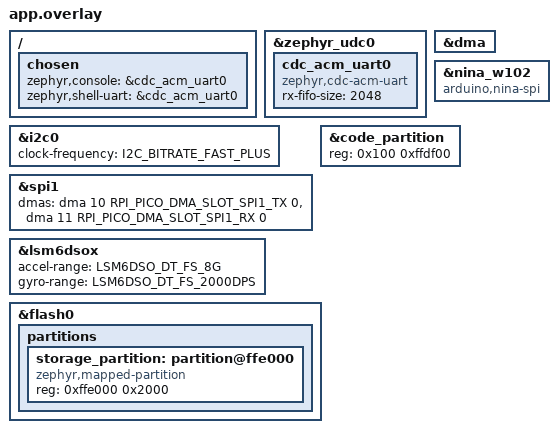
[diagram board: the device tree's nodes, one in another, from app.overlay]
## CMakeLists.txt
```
cmake_minimum_required(VERSION 3.28.0)
# The NINA-W102's devicetree binding (arduino,nina-spi) is its Zephyr binding's.
list(APPEND DTS_ROOT ${CMAKE_CURRENT_SOURCE_DIR}/../../../common/drivers/nina/port/zephyr)
# The LSM6DSO driver's Zephyr binding is a Zephyr module of its own (zephyr/module.yml there).
list(APPEND ZEPHYR_EXTRA_MODULES ${CMAKE_CURRENT_SOURCE_DIR}/../../../common/drivers/lsm6dso/port/zephyr)
find_package(Zephyr REQUIRED HINTS $ENV{ZEPHYR_BASE})
project(usb_console)

# Sources shared with the NuttX build.
set(COMMON_DIR ${CMAKE_CURRENT_SOURCE_DIR}/../../../common)
cmake_path(NORMAL_PATH COMMON_DIR)

target_sources(app PRIVATE src/main.c ${COMMON_DIR}/imu/app_main.c src/log_ram.c ${COMMON_DIR}/imu/kv_store.c ${COMMON_DIR}/imu/imu_cal.c
  ${COMMON_DIR}/imu/imu_cal_codec.c ${COMMON_DIR}/imu/wifi_profile.c
  ${COMMON_DIR}/imu/time_sync.c ${COMMON_DIR}/imu/time_offset.c
  ${COMMON_DIR}/imu/imu_stream.c ${COMMON_DIR}/imu/imu_raw_batch.c ${COMMON_DIR}/imu/imu_raw_packet.c
  ${COMMON_DIR}/imu/imu_raw_time.c ${COMMON_DIR}/imu/imu_tick_clock.c ${COMMON_DIR}/imu/imu_raw_queue.c
  ${COMMON_DIR}/imu/imu_raw_mqtt.c ${COMMON_DIR}/imu/imu_raw_status.c)
# Last below, common/chip/rp2040/include: the RP2040's code that no OS owns (the TIMER's read,
# the watchdog's restart), shared with the NuttX and FreeRTOS builds.
target_include_directories(app PRIVATE src ${COMMON_DIR}/imu
  ${COMMON_DIR}/drivers/nina/include ${COMMON_DIR}/drivers/nina/internal ${COMMON_DIR}/drivers/nina/port
  ${COMMON_DIR}/chip/rp2040/include)
# The LSM6DSO driver is the shared one of common/drivers/lsm6dso: its core and its Zephyr
# binding, a Zephyr module (port/zephyr, ZEPHYR_EXTRA_MODULES above) whose option
# CONFIG_LSM6DSO_LOCAL replaces Zephyr's CONFIG_LSM6DSO and whose build rules make a library of
# its own and export the driver's extended API <zephyr/drivers/sensor/lsm6dso.h>.  The sensor
# shell is Zephyr's with the local patch 0006 (manifest/zephyr/patches/zephyr).
# "kernel ps" (main.c): the interval arithmetic shared with the FreeRTOS build's "ps"
# (common/shell/include/ps_interval.h), and the kernel's internal headers for the interrupt stack
# (z_stack_space_get(), as Thread Analyzer).
set_property(SOURCE src/main.c APPEND PROPERTY INCLUDE_DIRECTORIES ${COMMON_DIR}/shell/include
  ${ZEPHYR_BASE}/kernel/include ${ZEPHYR_BASE}/arch/${ARCH}/include)

# NINA-W102: the shared core of common/drivers/nina (the Wi-Fi operations nina_wifi.c, the
# socket table and commands nina_sock.c, the resolver nina_dns.c; in internal/ the SPI link
# nina_proto.c and the socket loops' waits nina_wait.c), its Zephyr binding in
# common/drivers/nina/port/zephyr (the Wi-Fi management and network interface nina_net.c, the
# kernel services of port/nina_os.h nina_os.c: locks, requests, sleeps, clock, the READY and IRQ
# interrupts, the socket offload nina_socket.c, and spi1 and the module's lines from the
# devicetree nina_bus.c) and the "nina" command common/shell/nina_shell.c.  The core's POSIX
# socket names come from common/drivers/nina/port/zephyr/posix, on the include path of the
# socket sources only.  The binding's devicetree binding and options are its own
# (port/zephyr/dts/bindings, port/zephyr/Kconfig: DTS_ROOT above, the app's Kconfig).
set(nina_dir ${COMMON_DIR}/drivers/nina)
set(nina_internal_dir ${nina_dir}/internal)
set(nina_zephyr_dir ${nina_dir}/port/zephyr)
target_sources(app PRIVATE ${nina_internal_dir}/nina_proto.c ${nina_zephyr_dir}/nina_bus.c
  ${nina_zephyr_dir}/nina_os.c ${nina_dir}/nina_wifi.c ${nina_zephyr_dir}/nina_net.c ${nina_dir}/nina_sock.c
  ${nina_zephyr_dir}/nina_socket.c ${nina_dir}/nina_dns.c ${COMMON_DIR}/shell/nina_shell.c
  ${nina_internal_dir}/nina_wait.c)
# The NINA passthrough mode for esptool: the driver's core common/drivers/nina/nina_passthrough.c,
# its host's side on Zephyr's USB device stack (the binding's nina_passthrough_os.c) and its
# module's side on the Pico SDK's registers of hal_rpi_pico (the binding's
# nina_passthrough_bus_rp2040.c).  main() runs it on request, and "nina passthrough" is an entry
# of nina_shell.c's set.  While the mode is active nina_passthrough_active() keeps nina_bus.c
# from the module's lines.
if(CONFIG_NINA_PASSTHROUGH)
  target_sources(app PRIVATE ${nina_dir}/nina_passthrough.c ${nina_zephyr_dir}/nina_passthrough_os.c
    ${nina_zephyr_dir}/nina_passthrough_bus_rp2040.c)
endif()
set(nina_socket_sources ${nina_dir}/nina_sock.c ${nina_zephyr_dir}/nina_socket.c
  ${nina_dir}/nina_dns.c)
set_property(SOURCE ${nina_socket_sources} ${nina_zephyr_dir}/nina_net.c APPEND PROPERTY
  INCLUDE_DIRECTORIES ${nina_zephyr_dir}/posix)
# The resolver registered as the offload's, its results on nina_socket.c's heap (nina_os.h).
set_property(SOURCE ${nina_socket_sources} APPEND PROPERTY COMPILE_DEFINITIONS NINA_OS_DNS_OFFLOAD)
# Integer division through the SIO divider: the Pico SDK's pico_divider (hal_rpi_pico), as the
# SDK's pico_divider_hardware links it.  libgcc defines the plain names, so the references are
# wrapped to the SDK's __wrap___aeabi_idiv, ...  The routines save the divider when they
# interrupt a division (PICO_DIVIDER_DISABLE_INTERRUPTS=0); the thread switches save it
# (CONFIG_ARM_RP2040_DIVIDER_SAVE, manifest/zephyr/patches).  Division by zero still calls
# libgcc's __aeabi_idiv0 and __aeabi_ldiv0, which return; the 64-bit results are libgcc's, but a
# 32-bit quotient is then saturated (libgcc: 0) and the remainder 0 (libgcc: the dividend).
if(CONFIG_RP2040_PICO_DIVIDER)
  if(NOT CONFIG_ARM_RP2040_DIVIDER_SAVE)
    message(FATAL_ERROR "CONFIG_RP2040_PICO_DIVIDER needs CONFIG_ARM_RP2040_DIVIDER_SAVE: "
      "apply the local patches (source script/setup.sh)")
  endif()
  set(pico_src_dir ${ZEPHYR_HAL_RPI_PICO_MODULE_DIR}/src)
  set(divider_asm ${pico_src_dir}/rp2_common/pico_divider/divider_hardware.S)
  target_sources(app PRIVATE ${divider_asm})
  set_source_files_properties(${divider_asm} PROPERTIES
    COMPILE_DEFINITIONS PICO_DIVIDER_DISABLE_INTERRUPTS=0
    INCLUDE_DIRECTORIES "${pico_src_dir}/rp2_common/hardware_divider/include;${pico_src_dir}/rp2040/pico_platform/include")
  foreach(sym __aeabi_idiv __aeabi_idivmod __aeabi_uidiv __aeabi_uidivmod __aeabi_ldivmod
          __aeabi_uldivmod)
    zephyr_ld_options(-Wl,--wrap=${sym})
  endforeach()
endif()

# The DesignWare I2C driver is Zephyr's with a local patch (manifest/zephyr/patches/zephyr/
# 0003-i2c-dw-rp2040-fifo-and-dma.patch: the RP2040's FIFO depth and CONFIG_I2C_DW_RP2040_DMA,
# whole in Zephyr's tree). The "i2c_dma" command is the shared one
# (common/shell/i2c_dma_shell.c, on the functions of
# <zephyr/drivers/i2c/i2c_dw_rp2040_dma.h> that the patched driver defines).
if(CONFIG_I2C_DW_RP2040_DMA AND CONFIG_SHELL)
  target_sources(app PRIVATE ${COMMON_DIR}/shell/i2c_dma_shell.c)
endif()

# The code of the sensor's and the send's paths runs from RAM: the list and the check after the
# link are in ram_code.cmake.
include(ram_code.cmake)
```

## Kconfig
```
mainmenu "USB console"
source "Kconfig.zephyr"

config RP2040_PICO_DIVIDER
	bool "Integer division through the RP2040 hardware divider"
	default y
	depends on SOC_RP2040 && !SMP
	select ARM_RP2040_DIVIDER_SAVE
	help
	  Wrap __aeabi_idiv(), __aeabi_idivmod(), __aeabi_uidiv(),
	  __aeabi_uidivmod(), __aeabi_ldivmod() and __aeabi_uldivmod() (the
	  linker's --wrap) to the Pico SDK's pico_divider routines
	  (divider_hardware.S of hal_rpi_pico), which use the SIO divider.
	  Without it they are libgcc's shift-and-subtract loops. The routines
	  save the divider around their use when they interrupt another
	  division; the thread switches save and restore it
	  (ARM_RP2040_DIVIDER_SAVE, a local patch of Zephyr applied by
	  script/setup.sh).

rsource "../../../common/drivers/nina/port/zephyr/Kconfig"

config NINA_PASSTHROUGH
	bool "NINA passthrough mode for esptool"
	default y
	depends on WIFI_NINA_LOCAL && SOC_RP2040 && SHELL
	depends on USBD_CDC_ACM_CLASS && CDC_ACM_SERIAL_INITIALIZE_AT_BOOT && UART_LINE_CTRL
	help
	  The "nina passthrough confirm" command: a restart into a mode that
	  relays the USB CDC ACM port to the NINA-W102's UART (UART1 on
	  GPIO8 and GPIO9, the pins of the NINA's SPI link), with DTR and RTS
	  on the module's GPIO0 and RESETN, so that esptool on the PC reads
	  and writes the module's flash (common/drivers/nina/nina_passthrough.c).
	  Closing the port at 300 bps or the RESET button ends it.

config NINA_NTP_SERVER
	string "NTP server hostname or IPv4 address"
	default ""
	depends on WIFI_NINA_LOCAL
	help
	  Empty uses the default gateway, normally the PC that provides the
	  Wi-Fi network and runs an NTP server for the board.

config NINA_NTP_PORT
	int "NTP server UDP port"
	default 123
	range 1 65535
	depends on WIFI_NINA_LOCAL

config NINA_NTP_INTERVAL_MS
	int "Interval between NTP queries in milliseconds"
	default 2000
	range 250 3600000
	depends on WIFI_NINA_LOCAL
	help
	  Queries go to a server on the local network. Do not point short
	  intervals at public servers.

# The application's modules (common/imu), which this build always has.
# The NuttX build has the same symbols as options; the application's start
# (common/imu/app_main.c, common/imu/app_main.h) starts only the modules
# whose symbol is set.

config KV_STORE
	def_bool y
	help
	  The key-value store (common/imu/kv_store.c).

config APP_IMU
	def_bool y
	help
	  The IMU acquisition service with its calibration and the time
	  synchronization (common/imu/imu_stream.c, imu_cal.c, time_sync.c).

config WIFI_PROFILE
	def_bool y
	depends on WIFI_CREDENTIALS
	help
	  The Wi-Fi profile and its automatic connection
	  (common/imu/wifi_profile.c).
```

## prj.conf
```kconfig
CONFIG_SERIAL=y
CONFIG_CONSOLE=y
CONFIG_UART_CONSOLE=y
CONFIG_UART_LINE_CTRL=y
CONFIG_SHELL=y
CONFIG_SHELL_HISTORY=y
CONFIG_SHELL_BACKEND_SERIAL_RX_RING_BUFFER_SIZE=2048
CONFIG_SHELL_CMD_BUFF_SIZE=512
CONFIG_SHELL_STACK_SIZE=3072
CONFIG_MAIN_STACK_SIZE=2048
CONFIG_GPIO=y
CONFIG_GPIO_SHELL=y
CONFIG_I2C=y
CONFIG_SPI=y
CONFIG_I2C_SHELL=y
CONFIG_I2C_SHELL_BUFFER_SIZE=64
CONFIG_SENSOR=y
CONFIG_SENSOR_SHELL=y
CONFIG_SENSOR_SHELL_STREAM=y
CONFIG_SENSOR_SHELL_THREAD_STACK_SIZE=3072
CONFIG_STACK_SENTINEL=y
CONFIG_POLL=y
# The LSM6DSOX: the shared driver of common/drivers/lsm6dso (its Kconfig, sourced by the app's),
# not Zephyr's driver of the same devices.
CONFIG_LSM6DSO=n
CONFIG_LSM6DSO_LOCAL=y
CONFIG_REBOOT=y
# Reboot after a fatal error instead of halting; the report stays in the RAM log.
CONFIG_RESET_ON_FATAL_ERROR=y
# memcpy() and memset() through the bootrom's routines instead of picolibc's byte loops (a local
# patch of Zephyr, manifest/zephyr/patches, applied by script/setup.sh).
CONFIG_RP2040_ROM_MEM_OPS=y
# The code of the sensor's and the send's paths runs from RAM (ram_code.cmake).
CONFIG_CODE_DATA_RELOCATION=y
CONFIG_THREAD_ANALYZER=y
CONFIG_THREAD_ANALYZER_USE_PRINTK=y
CONFIG_LOG=y
CONFIG_LOG_OUTPUT=y
CONFIG_LOG_TIMESTAMP_64BIT=y
CONFIG_LOG_CMDS=y
CONFIG_LOG_RUNTIME_FILTERING=y
CONFIG_SHELL_LOG_BACKEND=n
CONFIG_LOG_BACKEND_UART=n

CONFIG_USB_DEVICE_STACK_NEXT=y
CONFIG_USBD_CDC_ACM_LOG_LEVEL_OFF=y
# Run the CDC ACM class (the USB shell's transmit completions) on its own work
# queue instead of the system work queue. There, zperf's idle_work_handler()
# waits for srv_lock, which "zperf tcp download stop" holds while it prints to
# the USB shell; the shell then waits for the work queue and both stop.
CONFIG_USBD_CDC_ACM_WORKQUEUE=y
CONFIG_CDC_ACM_SERIAL_INITIALIZE_AT_BOOT=y
CONFIG_CDC_ACM_SERIAL_PID=0x0004
CONFIG_CDC_ACM_SERIAL_PRODUCT_STRING="Zephyr USB Console"

# Measure active time from CPU idle windows, including interrupts.
CONFIG_CPU_LOAD=y
CONFIG_CPU_LOAD_BACKEND_IDLE_HOOK=y

# Use DMA for eligible I2C0 reads.
CONFIG_DMA=y
CONFIG_I2C_DW_RP2040_DMA=y

# The NINA's SPI1 through the DMA from 64 bytes (the channels in app.overlay);
# shorter transfers stay polled (patch 0007).
CONFIG_SPI_PL022_DMA=y
CONFIG_SPI_PL022_DMA_MIN_LEN=64

# NINA Wi-Fi management and socket offload.
CONFIG_NETWORKING=y
CONFIG_WIFI=y
CONFIG_WIFI_CREDENTIALS=y
CONFIG_WIFI_CREDENTIALS_BACKEND_SETTINGS=y
CONFIG_WIFI_NINA_LOCAL=y
CONFIG_NET_IPV4=y
CONFIG_NET_TCP=y
CONFIG_SHELL_BACKEND_TELNET=y
CONFIG_ZVFS_POLL_MAX=16
CONFIG_NET_ZPERF=y
CONFIG_NET_ZPERF_IPERF3=y
CONFIG_NET_ZPERF_SERVER=y
CONFIG_NET_L2_WIFI_SHELL=y
CONFIG_NET_SHELL=y
CONFIG_MQTT_LIB=y
# Network event callbacks may print Wi-Fi results through the shell. Measured
# peak use is 924 bytes including a Wi-Fi scan.
CONFIG_NET_MGMT_EVENT_STACK_SIZE=2048
# Every socket is offloaded to the NINA module, so Zephyr's own IP stack
# carries nothing: no receive thread, and a small stack for the TCP work
# queue (measured use 304 bytes).
CONFIG_NET_TC_RX_COUNT=0
CONFIG_NET_TCP_WORKQ_STACK_SIZE=512
# The longest thread name has 18 characters (the default length is 32).
CONFIG_THREAD_MAX_NAME_LEN=20
# Every socket is offloaded to the NINA, so Zephyr's own IP stack carries no
# traffic ("net conn" stays empty). Keep its packet buffers and connection
# tables at a minimum instead of the defaults sized for native networking.
CONFIG_NET_PKT_RX_COUNT=2
CONFIG_NET_PKT_TX_COUNT=2
CONFIG_NET_BUF_RX_COUNT=4
CONFIG_NET_BUF_TX_COUNT=4
CONFIG_NET_MAX_CONTEXTS=2
CONFIG_NET_MAX_CONN=2
# Zephyr derives the size of the file descriptor table from NET_MAX_CONTEXTS,
# which no longer reflects the sockets in use. Size it for the ten NINA
# sockets, stdin/stdout/stderr and the socket service's eventfd. With too few,
# accepting a Telnet client fails in a tight loop.
CONFIG_ZVFS_OPEN_MAX=16
CONFIG_WIFI_ESP_AT=n
# Temporary non-cryptographic random generator for network testing; no TLS.
CONFIG_TEST_RANDOM_GENERATOR=y
CONFIG_NET_IPV6=n

# Persist the most recently successful Wi-Fi connection.
CONFIG_FLASH=y
CONFIG_FLASH_MAP=y
CONFIG_NVS=y
CONFIG_SETTINGS=y
CONFIG_SETTINGS_NVS=y

# Identifies the board in automatically assigned IMU session IDs.
CONFIG_HWINFO=y
```

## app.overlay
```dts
#include <zephyr/dt-bindings/dma/rpi-pico-dma-rp2040.h>
#include <zephyr/dt-bindings/sensor/lsm6dso.h>

/ {
	chosen {
		zephyr,console = &cdc_acm_uart0;
		zephyr,shell-uart = &cdc_acm_uart0;
	};
};

&zephyr_udc0 {
	cdc_acm_uart0: cdc_acm_uart0 {
		compatible = "zephyr,cdc-acm-uart";
		rx-fifo-size = <2048>;
	};
};

&dma {
	status = "okay";
};

/* 1 MHz from the start (the board's file has 100 kHz): the LSM6DSOX is
 * alone on this bus, and its FIFO from 833 Hz up fills faster than 100 kHz
 * can empty it, at 6667 Hz faster than 400 kHz can.
 */
&i2c0 {
	clock-frequency = <I2C_BITRATE_FAST_PLUS>;
};

/* The NINA's long transfers through DMA channels 10 (TX) and 11 (RX), which
 * the PL022 driver requests at boot; the I2C0 reads take free channels from
 * channel 0 up.
 */
&spi1 {
	status = "okay";
	dmas = <&dma 10 RPI_PICO_DMA_SLOT_SPI1_TX 0>, <&dma 11 RPI_PICO_DMA_SLOT_SPI1_RX 0>;
	dma-names = "tx", "rx";
};

/* Wide ranges: the noise at 6667 Hz is well above one LSB even here, and a
 * saturated gyro sample cannot be recovered afterwards.
 */
&lsm6dsox {
	accel-range = <LSM6DSO_DT_FS_8G>;
	gyro-range = <LSM6DSO_DT_FS_2000DPS>;
};

&nina_w102 {
	compatible = "arduino,nina-spi";
};

/* Reserve the last two erase sectors for settings; keep the image separate. */
&code_partition {
	reg = <0x100 0xffdf00>;
};

&flash0 {
	partitions {
		storage_partition: partition@ffe000 {
			compatible = "zephyr,mapped-partition";
			reg = <0xffe000 0x2000>;
		};
	};
};
```

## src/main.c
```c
#include <string.h>
#include <zephyr/kernel.h>
#include <zephyr/shell/shell.h>
#include <pico/bootrom.h>
#include "app_main.h"
#include "nina_passthrough.h"

/* "kernel ps": each thread's share of the CPU time since the previous
 * "kernel ps" (since the start for the first), from any shell, and the use
 * of its stack, then the interrupt stack, as Thread Analyzer
 * (subsys/debug/thread_analyzer) shows them.  Thread Analyzer's own CPU
 * figure is the share since the start, and its callback does not say which
 * thread a row is, so the threads are read here: the runtime statistics
 * (CONFIG_SCHED_THREAD_USAGE, cycles counted at each switch; interrupt
 * handlers count in the thread they interrupted) of this list less those of
 * the previous one, for each thread by its handle
 * (common/shell/include/ps_interval.h; nothing runs between two lists).  The share
 * is of all the cycles of the interval (execution_cycles of
 * k_thread_runtime_stats_all_get(): non-idle and idle), so the rows, the
 * idle thread's included, add up to about 100%.
 */
#define PS_INTERVAL_TASKS_MAX 32
#include "ps_interval.h"

/* For z_stack_space_get(), as Thread Analyzer and "kernel thread stacks". */
#include <kernel_internal.h>

K_KERNEL_STACK_ARRAY_DECLARE(z_interrupt_stacks, CONFIG_MP_MAX_NUM_CPUS, CONFIG_ISR_STACK_SIZE);

struct ps_thread {
	k_tid_t tid;
	char name[CONFIG_THREAD_MAX_NAME_LEN];
	size_t stack_size;
	size_t stack_unused;
	int stack_err;
	uint64_t cycles;
};

/* Under ps_lock. */
K_MUTEX_DEFINE(ps_lock);
static struct ps_thread ps_threads[PS_INTERVAL_TASKS_MAX];
static size_t ps_count;
static size_t ps_more;
static struct ps_interval ps_interval;

static void ps_read_thread(const struct k_thread *cthread, void *user_data)
{
	struct k_thread *thread = (struct k_thread *)cthread;
	struct ps_thread *t;
	k_thread_runtime_stats_t usage;
	const char *name;

	ARG_UNUSED(user_data);
	if (ps_count >= ARRAY_SIZE(ps_threads)) {
		ps_more++;
		return;
	}
	t = &ps_threads[ps_count++];
	t->tid = thread;
	name = k_thread_name_get(thread);
	if (name != NULL && name[0] != '\0') {
		strncpy(t->name, name, sizeof(t->name) - 1);
		t->name[sizeof(t->name) - 1] = '\0';
	} else {
		snprintk(t->name, sizeof(t->name), "%p", (void *)thread);
	}
	t->stack_size = thread->stack_info.size;
	t->stack_err = k_thread_stack_space_get(thread, &t->stack_unused);
	if (t->stack_err != 0) {
		t->stack_unused = 0;
	}
	t->cycles = 0;
	if (k_thread_runtime_stats_get(thread, &usage) == 0) {
		t->cycles = usage.execution_cycles;
	}
}

static int cmd_ps(const struct shell *sh, size_t argc, char **argv)
{
	k_thread_runtime_stats_t all = {0};
	uint64_t elapsed;
	uint32_t hz = sys_clock_hw_cycles_per_sec();

	ARG_UNUSED(argc);
	ARG_UNUSED(argv);
	k_mutex_lock(&ps_lock, K_FOREVER);
	ps_count = 0;
	ps_more = 0;
	k_thread_foreach_unlocked(ps_read_thread, NULL);
	/* After the threads: the interval is not shorter than their times. */
	(void)k_thread_runtime_stats_all_get(&all);

	elapsed = ps_interval_begin(&ps_interval, all.execution_cycles);
	for (size_t i = 0; i < ps_count; i++) {
		struct ps_thread *t = &ps_threads[i];
		uint64_t run = ps_interval_task(&ps_interval, (uintptr_t)t->tid, 0, t->cycles);
		unsigned int permille = ps_interval_permille(run, elapsed);

		if (t->stack_err != 0) {
			shell_print(sh, " %-20s: unable to get stack space (%d)", t->name,
				    t->stack_err);
		}
		shell_print(sh, "%-20s CPU: %3u.%u%%  STACK: %zu / %zu bytes", t->name,
			    permille / 10, permille % 10, t->stack_size - t->stack_unused,
			    t->stack_size);
	}
	ps_interval_end(&ps_interval);
	if (ps_more != 0) {
		shell_print(sh, "(%zu more threads not shown)", ps_more);
	}

	for (unsigned int i = 0; i < arch_num_cpus(); i++) {
		const uint8_t *buf = K_KERNEL_STACK_BUFFER(z_interrupt_stacks[i]);
		size_t size = K_KERNEL_STACK_SIZEOF(z_interrupt_stacks[i]);
		size_t unused;

		if (z_stack_space_get(buf, size, &unused) == 0) {
			shell_print(sh, "ISR%-17u CPU: %6s  STACK: %zu / %zu bytes", i, "-",
				    size - unused, size);
		}
	}
	shell_print(sh, "CPU: share of the %llu.%03llu s since the previous \"kernel ps\"",
		    (unsigned long long)(elapsed / hz),
		    (unsigned long long)(elapsed % hz * 1000u / hz));
	k_mutex_unlock(&ps_lock);
	return 0;
}

SHELL_SUBCMD_ADD((kernel), ps, NULL, "Show thread CPU and stack usage", cmd_ps,
		 1, 0);

/* Time for the shell to send the command's last line before a restart. */
#define RESTART_DELAY_MS 100

/* Restarts into the boot ROM's USB loader (the RPI-RP2 drive), as holding
 * BOOTSEL at reset does: the ROM's reset_usb_boot() (hal_rpi_pico's
 * pico_bootrom, which Zephyr's SoC code calls for its retention boot mode),
 * with both of its interfaces and no activity LED, as the FreeRTOS build's
 * "bootsel".
 */
static int cmd_bootsel(const struct shell *sh, size_t argc, char **argv)
{
	ARG_UNUSED(argc);
	ARG_UNUSED(argv);
	shell_print(sh, "Entering BOOTSEL (the RPI-RP2 drive)");
	k_msleep(RESTART_DELAY_MS);
	reset_usb_boot(0, 0);
}

SHELL_CMD_REGISTER(bootsel, NULL, "Restart into the USB bootloader (BOOTSEL)", cmd_bootsel);

/* The kernel has run the application's SYS_INIT() parts and started its
 * K_THREAD_DEFINE() threads before this (common/imu/app_main.h).
 */
int main(void)
{
	/* "nina passthrough confirm" asked for the NINA passthrough mode
	 * (common/drivers/nina/include/nina_passthrough.h): it runs instead of all that
	 * follows (no settings, no Wi-Fi, no time synchronization), until it
	 * restarts the board into the normal firmware.
	 */
#ifdef CONFIG_NINA_PASSTHROUGH
	if (nina_passthrough_active()) {
		nina_passthrough_run();
	}
#endif

	app_main();
	return 0;
}
```

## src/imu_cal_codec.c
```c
/* SPDX-License-Identifier: Apache-2.0 */

#include <errno.h>
#include <stdio.h>
#include "imu_cal.h"

static uint32_t get_le32(const uint8_t *p)
{
	return (uint32_t)p[0] | (uint32_t)p[1] << 8 | (uint32_t)p[2] << 16 | (uint32_t)p[3] << 24;
}

int imu_cal_key(enum lsm6dso_cal_kind kind, uint32_t gain, char *key, size_t capacity)
{
	int len = snprintf(key, capacity, "imu.cal.%s.%u",
			   kind == LSM6DSO_CAL_ACCEL ? "accel" : "gyro", (unsigned int)gain);

	return len < 0 || (size_t)len >= capacity ? -ENAMETOOLONG : len;
}

int imu_cal_decode(const uint8_t *blob, size_t len, enum lsm6dso_cal_kind kind, uint32_t gain,
		   struct lsm6dso_cal *cal)
{
	if (len != IMU_CAL_BLOB_SIZE || blob[0] != IMU_CAL_VERSION || blob[2] != 0 || blob[3] != 0) {
		return -EINVAL;
	}
	if (blob[1] != (kind == LSM6DSO_CAL_ACCEL ? 0 : 1) || get_le32(blob + 4) != gain) {
		return -ENOENT;
	}
	for (int i = 0; i < 9; i++) {
		cal->m[i / 3][i % 3] = (int32_t)get_le32(blob + 8 + 4 * i);
	}
	for (int i = 0; i < 3; i++) {
		cal->bias[i] = (int32_t)get_le32(blob + 44 + 4 * i);
	}
	return 0;
}
```

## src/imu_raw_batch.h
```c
/* SPDX-License-Identifier: Apache-2.0 */
#ifndef IMU_RAW_BATCH_H_
#define IMU_RAW_BATCH_H_

#include "imu_raw_packet.h"
#include "imu_raw_time.h"

/* Runs in the FIFO consumer. The sink must not wait or retain payload; it
 * returns 0 after copying or -EAGAIN if it cannot accept the batch. */
typedef int (*imu_raw_batch_sink)(void *context, const uint8_t *payload, size_t length);
/* Optional: server (Unix) time in microseconds for a sensor tick. Called at
 * most twice per batch with ticks that never decrease. Must not wait long. */
typedef bool (*imu_raw_batch_clock)(void *context, uint64_t tick, uint64_t *unix_us);

struct imu_raw_batch {
	struct imu_raw_metadata meta;
	uint8_t payload[IMU_RAW_MAX_SIZE]; /* built in place, see imu_raw_stage_put() */
	uint64_t next_accel, next_gyro, next_batch;
	uint64_t delivered_batches, dropped_batches, dropped_accel, dropped_gyro;
	uint64_t timestamp_words;
	struct imu_raw_time time;
	size_t count, accel_count; /* words in the batch being built */
	/* A first tick was noted and awaits confirmation; see imu_raw_time.h. */
	bool accel_tick_noted, gyro_tick_noted;
	uint32_t accel_tick_generation, gyro_tick_generation;
	uint64_t accel_noted_tick, gyro_noted_tick;
	imu_raw_batch_sink sink;
	void *sink_context;
	imu_raw_batch_clock clock; /* set after init; NULL leaves Unix time invalid */
	void *clock_context;
};

/* The caller supplies a unique session ID; no random ID is generated here. */
int imu_raw_batch_init(struct imu_raw_batch *batch, const uint8_t session_id[16],
		       uint32_t epoch_id, imu_raw_batch_sink sink, void *context);
/* cursor is a byte offset into a FIFO word array. Each valid sample is
 * numbered before the sink is called. The first accelerometer and gyroscope
 * sample of a batch carry their sensor tick when imu_raw_time can assign one
 * and has confirmed it by the time the batch is flushed; otherwise the
 * time-valid flag stays clear.
 * Unsupported tags return -EPROTO without consuming the offending word.
 */
int imu_raw_batch_consume(struct imu_raw_batch *batch, const uint8_t *words,
			  size_t length, size_t *cursor);
/* Flush the incomplete batch at a deadline, stop, or before an epoch change. */
int imu_raw_batch_flush(struct imu_raw_batch *batch);
/* Call after an unknown number of samples was lost (FIFO overrun, restart,
 * unparsable word). Flushes what was collected and starts the next epoch.
 * Batch and sample numbers keep counting so they stay unique in the session;
 * consecutive numbers on both sides of an epoch change do not mean that the
 * samples are contiguous. On a flush error the epoch is left unchanged.
 */
int imu_raw_batch_new_epoch(struct imu_raw_batch *batch);
#endif
```

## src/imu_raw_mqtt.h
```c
/* SPDX-License-Identifier: Apache-2.0 */
#ifndef IMU_RAW_MQTT_H_
#define IMU_RAW_MQTT_H_
#include <stdbool.h>
#include <stddef.h>
#include <stdint.h>
#include <zephyr/net/net_ip.h>
#include "imu_raw_status.h"

/* MQTT transport for RAW batches (QoS 0), info and status. It owns a bounded
 * queue: batches are dropped and counted while disconnected or when the
 * queue is full, never retried. Thread context only. */
#define IMU_RAW_MQTT_DEVICE_ID_MAX 40

struct imu_raw_mqtt_config {
	/* 0.0.0.0 means the default gateway, looked up again for every
	 * connection attempt: the session then follows the network the board
	 * is on, and can be started before Wi-Fi is connected. */
	struct in_addr address;
	uint16_t port;
	/* Letters, digits, '-' and '_'; used in topics and the client ID. */
	char device_id[IMU_RAW_MQTT_DEVICE_ID_MAX + 1];
	uint8_t session_id[16];
};

struct imu_raw_mqtt_stats {
	bool running, connected;
	bool via_gateway;       /* no fixed address configured */
	struct in_addr address; /* of the latest connection attempt; 0 if none */
	uint16_t port;
	size_t queued, queue_high;
	uint32_t published; /* accepted by the socket, not confirmed delivered */
	uint32_t failures, connects, status_published, info_published;
	uint64_t dropped_batches, dropped_accel, dropped_gyro;
	uint64_t lock_wait_count, lock_wait_total_us, lock_wait_max_us;
	uint64_t publish_total_us, publish_max_us, publish_bytes;
};

/* -EBUSY while a previous session is still shutting down, -EINVAL for a bad
 * device ID or port. Counters restart. */
int imu_raw_mqtt_start(const struct imu_raw_mqtt_config *config);
/* Gives a final status up to half a second to leave, then disconnects. */
void imu_raw_mqtt_stop(void);
/* Sink for imu_raw_batch. May wait for the queue mutex; never waits on the
 * network. Returns -EAGAIN for a batch that was dropped. */
int imu_raw_mqtt_submit(void *context, const uint8_t *payload, size_t length);
/* Neither waits on the network. Info is published on every (re)connection and
 * when it changes; status periodically, on (re)connection and when the state
 * changes. Only the acquisition fields of *status are used. Nothing is kept
 * for a disconnected period. */
void imu_raw_mqtt_set_info(const struct imu_raw_info *info);
void imu_raw_mqtt_report(const struct imu_raw_status *status);
void imu_raw_mqtt_get_stats(struct imu_raw_mqtt_stats *stats);
#endif
```

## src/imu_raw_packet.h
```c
/* SPDX-License-Identifier: Apache-2.0 */
#ifndef IMU_RAW_PACKET_H_
#define IMU_RAW_PACKET_H_

#include <stddef.h>
#include <stdint.h>
#include "../drivers/lsm6dso/lsm6dso_fifo.h"

/* Experimental payload based on design/imu-raw-mqtt-design-ja.md §6.
 * Version 2 appends the server (Unix) time of the first sample of each kind
 * to the version 1 header:
 *   80  u64  accel_first_unix_us
 *   88  u64  gyro_first_unix_us
 * and uses flag bits 2 and 3 for their validity. Everything before offset 80
 * is laid out as in version 1.
 */
#define IMU_RAW_VERSION 2U
#define IMU_RAW_HEADER_SIZE 96U
#define IMU_RAW_MAX_WORDS 384U
#define IMU_RAW_MAX_BITMAP ((IMU_RAW_MAX_WORDS + 7U) / 8U)
#define IMU_RAW_MAX_SIZE (IMU_RAW_HEADER_SIZE + IMU_RAW_MAX_BITMAP + 6U * IMU_RAW_MAX_WORDS)
#define IMU_RAW_ACCEL_TIME_VALID 1U
#define IMU_RAW_GYRO_TIME_VALID 2U
#define IMU_RAW_ACCEL_UNIX_VALID 4U
#define IMU_RAW_GYRO_UNIX_VALID 8U
#define IMU_RAW_FLAGS_MASK 15U

struct imu_raw_metadata {
	uint8_t session_id[16];
	uint64_t batch_seq;
	uint64_t accel_first_index, gyro_first_index;
	uint64_t accel_first_tick, gyro_first_tick;
	/* Microseconds since 1970 as estimated by the board when the batch was
	 * built. Derived from the tick, so it needs the tick to be valid. */
	uint64_t accel_first_unix_us, gyro_first_unix_us;
	uint32_t epoch_id, time_map_id;
	uint8_t flags;
};

/* Encodes one complete payload. The caller owns numbering, timing, and transport.
 * An absent sensor must have index UINT64_MAX and tick 0; invalid time has tick 0
 * and an invalid Unix time is 0.
 * On error, *written is set to zero and no output bytes are changed.
 */
int imu_raw_encode(uint8_t *out, size_t capacity, size_t *written,
		   const struct imu_raw_metadata *meta,
		   const struct lsm6dso_fifo_sample *samples, size_t count);

/* The same payload built one word at a time in a buffer of IMU_RAW_MAX_SIZE
 * bytes, so that the samples need not be kept elsewhere first:
 *   imu_raw_stage_reset(), then imu_raw_stage_put() for words 0, 1, 2, ...,
 *   then imu_raw_stage_finish(), which leaves the complete payload in place.
 * `accel` is the number of accelerometer words among the `count` put.
 * After finish the buffer must be reset before the next payload, or reopened
 * with the same count to continue adding to this one. An error from finish
 * leaves the staged words untouched.
 */
void imu_raw_stage_reset(uint8_t *payload);
void imu_raw_stage_put(uint8_t *payload, size_t index, const struct lsm6dso_fifo_sample *sample);
int imu_raw_stage_finish(uint8_t *payload, size_t *written, const struct imu_raw_metadata *meta,
			 size_t count, size_t accel);
void imu_raw_stage_reopen(uint8_t *payload, size_t count);
#endif
```

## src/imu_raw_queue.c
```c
/* SPDX-License-Identifier: Apache-2.0 */
#include "imu_raw_queue.h"

#include <errno.h>
#include <string.h>

static uint16_t le16(const uint8_t *p)
{
	return (uint16_t)p[0] | ((uint16_t)p[1] << 8);
}

void imu_raw_queue_init(struct imu_raw_queue *queue)
{
	if (queue) {
		memset(queue, 0, sizeof(*queue));
	}
}

void imu_raw_queue_discard(struct imu_raw_queue *queue, const struct imu_raw_queue_item *item)
{
	if (!queue || !item) {
		return;
	}
	queue->dropped_batches++;
	queue->dropped_accel += item->accel_count;
	queue->dropped_gyro += item->gyro_count;
}

void imu_raw_queue_set_connected(struct imu_raw_queue *queue, bool connected)
{
	if (!queue) {
		return;
	}
	queue->connected = connected;
	if (!connected) {
		while (queue->count) {
			imu_raw_queue_discard(queue, &queue->items[queue->head]);
			queue->head = (queue->head + 1) % IMU_RAW_QUEUE_CAPACITY;
			queue->count--;
		}
	}
}

int imu_raw_queue_put(struct imu_raw_queue *queue, const uint8_t *payload, size_t length)
{
	struct imu_raw_queue_item *item;
	uint16_t count, bitmap, accel = 0;

	if (!queue || !payload || length < IMU_RAW_HEADER_SIZE ||
	    memcmp(payload, "IMU1", 4) || payload[4] != IMU_RAW_VERSION ||
	    le16(payload + 6) != IMU_RAW_HEADER_SIZE) {
		return -EINVAL;
	}
	count = le16(payload + 64);
	bitmap = le16(payload + 66);
	if (!count || count > IMU_RAW_MAX_WORDS || bitmap != (count + 7) / 8 ||
	    length != IMU_RAW_HEADER_SIZE + bitmap + (size_t)count * 6) {
		return -EINVAL;
	}
	for (size_t i = 0; i < count; i++) {
		accel += (payload[IMU_RAW_HEADER_SIZE + i / 8] >> (i % 8)) & 1U;
	}
	if (!queue->connected || queue->count == IMU_RAW_QUEUE_CAPACITY) {
		queue->dropped_batches++;
		queue->dropped_accel += accel;
		queue->dropped_gyro += count - accel;
		return -EAGAIN;
	}
	item = &queue->items[(queue->head + queue->count) % IMU_RAW_QUEUE_CAPACITY];
	item->length = length;
	item->accel_count = accel;
	item->gyro_count = count - accel;
	memcpy(item->payload, payload, length);
	queue->count++;
	if (queue->count > queue->high_watermark) {
		queue->high_watermark = queue->count;
	}
	return 0;
}

int imu_raw_queue_take(struct imu_raw_queue *queue, struct imu_raw_queue_item *item)
{
	if (!queue || !item) {
		return -EINVAL;
	}
	if (!queue->connected || !queue->count) {
		return -EAGAIN;
	}
	*item = queue->items[queue->head];
	queue->head = (queue->head + 1) % IMU_RAW_QUEUE_CAPACITY;
	queue->count--;
	return 0;
}
```

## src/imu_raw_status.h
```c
/* SPDX-License-Identifier: Apache-2.0 */
#ifndef IMU_RAW_STATUS_H_
#define IMU_RAW_STATUS_H_

#include <stdbool.h>
#include <stddef.h>
#include <stdint.h>

/* Experimental JSON for imu/<device_id>/status and imu/<device_id>/info
 * (design/imu-raw-mqtt-design-ja.md §5). Batch ticks are in the sensor's own
 * clock; conversion to host time is not implemented and status says so. */
enum imu_raw_state {
	IMU_RAW_STATE_IDLE,      /* session configured, no measurement yet */
	IMU_RAW_STATE_MEASURING,
	IMU_RAW_STATE_STOPPED,
};

struct imu_raw_status {
	/* Filled by the acquisition side. Numbers advance whether or not a
	 * batch was sent, so they are the reference for detecting loss. */
	uint8_t session_id[16];
	enum imu_raw_state state;
	uint32_t epoch_id;
	uint64_t uptime_ms;
	uint64_t accel_acquired, gyro_acquired, next_batch, timestamp_words;
	uint32_t fifo_overrun_observations, i2c_errors;
	int raw_error, measure_error;
	/* One reading of the sensor's tick counter and the board clock taken
	 * together, with the board's estimate of server (Unix) time for that
	 * instant. The receiver relates batch ticks to its own time from a
	 * series of these; the board does not convert sample times itself. */
	bool tick_valid, unix_valid;
	uint64_t tick;              /* extended like the batch ticks */
	int64_t tick_mono_us;       /* board clock at the middle of the read */
	uint32_t tick_window_us;    /* duration of the read */
	int64_t unix_us;            /* smoothed: strictly increasing */
	int64_t unix_estimate_us;   /* unsmoothed: may jump either way */
	uint32_t sync_delay_us;     /* round trip behind the estimate */
	/* Filled by the transport. */
	uint64_t dropped_batches, dropped_accel, dropped_gyro, published;
	uint32_t connects, failures, queue_high_watermark;
};

struct imu_raw_info {
	uint8_t session_id[16];
	uint32_t epoch_id;
	uint16_t accel_odr_hz, gyro_odr_hz; /* configured, not measured */
	uint32_t accel_ug_per_lsb, gyro_udps_per_lsb;
	uint16_t fifo_watermark;
	uint8_t timestamp_decimation;
	/* Sensor clock: one tick is 1 / (40000 * (1 + 0.0015 * freq_fine)) s per
	 * the LSM6DSO datasheet. Not related to host time. */
	int8_t freq_fine;
};

/* Both return the JSON length (without a terminator being counted) or
 * -ENOSPC/-EINVAL. The output is always NUL-terminated on success. */
int imu_raw_status_encode(char *out, size_t capacity, const struct imu_raw_status *status);
int imu_raw_info_encode(char *out, size_t capacity, const struct imu_raw_info *info,
			const char *device_id);
#endif
```

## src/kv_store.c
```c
/* SPDX-License-Identifier: Apache-2.0 */
#include <errno.h>
#include <string.h>
#include <zephyr/settings/settings.h>
#include <zephyr/shell/shell.h>
#include <zephyr/sys/util.h>
#include "kv_store.h"

#define KV_PREFIX        "app_kv/"
#define KV_SYSTEM_PREFIX "sys."

static bool shell_key_allowed(const char *key)
{
	return strncmp(key, KV_SYSTEM_PREFIX, sizeof(KV_SYSTEM_PREFIX) - 1) !=
	       0;
}

static int make_name(const char *key, char *name, size_t capacity)
{
	size_t len;

	if (!key) {
		return -EINVAL;
	}
	len = strnlen(key, KV_STORE_KEY_MAX + 1);
	if (!len || len > KV_STORE_KEY_MAX) {
		return -EINVAL;
	}
	for (size_t i = 0; i < len; i++) {
		char c = key[i];

		if (!((c >= 'a' && c <= 'z') || (c >= 'A' && c <= 'Z') ||
		      (c >= '0' && c <= '9') || c == '_' || c == '-' ||
		      c == '.')) {
			return -EINVAL;
		}
	}
	if (sizeof(KV_PREFIX) + len > capacity) {
		return -ENAMETOOLONG;
	}
	memcpy(name, KV_PREFIX, sizeof(KV_PREFIX) - 1);
	memcpy(name + sizeof(KV_PREFIX) - 1, key, len + 1);
	return 0;
}

int kv_store_init(void)
{
	return settings_subsys_init();
}

int kv_store_set(const char *key, const void *value, size_t len)
{
	char name[sizeof(KV_PREFIX) + KV_STORE_KEY_MAX];
	int ret = make_name(key, name, sizeof(name));

	if (ret) {
		return ret;
	}
	if (!value || !len || len > KV_STORE_VALUE_MAX) {
		return -EINVAL;
	}
	ret = kv_store_init();
	if (ret) {
		return ret;
	}
	return settings_save_one(name, value, len);
}

ssize_t kv_store_get(const char *key, void *value, size_t capacity)
{
	char name[sizeof(KV_PREFIX) + KV_STORE_KEY_MAX];
	ssize_t len;
	int ret = make_name(key, name, sizeof(name));

	if (ret) {
		return ret;
	}
	if (!value || !capacity) {
		return -EINVAL;
	}
	ret = kv_store_init();
	if (ret) {
		return ret;
	}
	len = settings_load_one(name, value, capacity);
	if (len == 0) {
		return -ENOENT;
	}
	if (len > 0 && (size_t)len > capacity) {
		return -ENOBUFS;
	}
	return len;
}

int kv_store_delete(const char *key)
{
	char name[sizeof(KV_PREFIX) + KV_STORE_KEY_MAX];
	int ret = make_name(key, name, sizeof(name));

	if (ret) {
		return ret;
	}
	ret = kv_store_init();
	return ret ? ret : settings_delete(name);
}

static int cmd_set(const struct shell *sh, size_t argc, char **argv)
{
	int ret;

	ARG_UNUSED(argc);
	if (!shell_key_allowed(argv[1])) {
		shell_error(sh, "Reserved key");
		return -EACCES;
	}
	ret = kv_store_set(argv[1], argv[2], strlen(argv[2]));
	if (ret) {
		shell_error(sh, "KV write failed: %d", ret);
	} else {
		shell_print(sh, "Saved");
	}
	return ret;
}

static int cmd_sethex(const struct shell *sh, size_t argc, char **argv)
{
	uint8_t value[KV_STORE_VALUE_MAX];
	size_t chars = strlen(argv[2]);
	size_t len;
	int ret;

	ARG_UNUSED(argc);
	if (!shell_key_allowed(argv[1])) {
		shell_error(sh, "Reserved key");
		return -EACCES;
	}
	if (!chars || chars % 2 || chars > sizeof(value) * 2) {
		shell_error(sh, "Expected 1-128 bytes as hexadecimal pairs");
		return -EINVAL;
	}
	len = hex2bin(argv[2], chars, value, sizeof(value));
	if (len != chars / 2) {
		shell_error(sh, "Invalid hexadecimal value");
		return -EINVAL;
	}
	ret = kv_store_set(argv[1], value, len);
	if (ret) {
		shell_error(sh, "KV write failed: %d", ret);
	} else {
		shell_print(sh, "Saved");
	}
	return ret;
}

static int cmd_get(const struct shell *sh, size_t argc, char **argv)
{
	uint8_t value[KV_STORE_VALUE_MAX];
	char hex[2 * KV_STORE_VALUE_MAX + 1];
	ssize_t len;

	ARG_UNUSED(argc);
	if (!shell_key_allowed(argv[1])) {
		shell_error(sh, "Reserved key");
		return -EACCES;
	}
	len = kv_store_get(argv[1], value, sizeof(value));
	if (len < 0) {
		shell_error(sh, "KV read failed: %d", (int)len);
		return (int)len;
	}
	bin2hex(value, len, hex, sizeof(hex));
	shell_print(sh, "%s", hex);
	return 0;
}

static int cmd_delete(const struct shell *sh, size_t argc, char **argv)
{
	int ret;

	ARG_UNUSED(argc);
	if (!shell_key_allowed(argv[1])) {
		shell_error(sh, "Reserved key");
		return -EACCES;
	}
	ret = kv_store_delete(argv[1]);
	if (ret) {
		shell_error(sh, "KV delete failed: %d", ret);
	} else {
		shell_print(sh, "Deleted");
	}
	return ret;
}

SHELL_STATIC_SUBCMD_SET_CREATE(
	kv_commands,
	SHELL_CMD_ARG(set, NULL, "Store a text value: <key> <value>", cmd_set,
		      3, 0),
	SHELL_CMD_ARG(sethex, NULL, "Store hex bytes: <key> <hex>", cmd_sethex,
		      3, 0),
	SHELL_CMD_ARG(get, NULL, "Print a value as hex: <key>", cmd_get, 2, 0),
	SHELL_CMD_ARG(delete, NULL, "Delete a value: <key>", cmd_delete, 2, 0),
	SHELL_SUBCMD_SET_END);
SHELL_CMD_REGISTER(kv, &kv_commands, "Application key-value storage", NULL);
```

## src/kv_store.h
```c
/* SPDX-License-Identifier: Apache-2.0 */
#ifndef APP_KV_STORE_H_
#define APP_KV_STORE_H_

#include <stddef.h>
#include <sys/types.h>

#define KV_STORE_KEY_MAX   32
#define KV_STORE_VALUE_MAX 128

/* Keys contain ASCII letters, digits, '.', '-' or '_'. Values are binary.
 * A zero-length value is not supported. Data is stored without encryption.
 * All calls must run in thread context and return negative errno on failure.
 */
int kv_store_init(void);
int kv_store_set(const char *key, const void *value, size_t len);
/* Returns the value length; -ENOENT if absent, -ENOBUFS if too small. */
ssize_t kv_store_get(const char *key, void *value, size_t capacity);
int kv_store_delete(const char *key);

#endif
```

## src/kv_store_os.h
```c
/* SPDX-License-Identifier: MIT */
/* The Zephyr part of common/imu/kv_store.c: the "kv" command has no
 * subcommands of the OS's (the other builds add "kv wipe",
 * common/compat/include/kv_store_os.h).
 */
#ifndef APP_KV_STORE_OS_H_
#define APP_KV_STORE_OS_H_

#define KV_STORE_OS_COMMANDS

#endif
```

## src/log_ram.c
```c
#include <zephyr/kernel.h>
#include <zephyr/linker/section_tags.h>
#include <zephyr/logging/log_backend.h>
#include <zephyr/logging/log_ctrl.h>
#include <zephyr/logging/log_msg.h>
#include <zephyr/logging/log_output.h>
#include <zephyr/shell/shell.h>

#define LOG_RAM_SIZE 4096
#define LOG_RAM_MAGIC 0x4c4f4752U

struct retained_log {
	uint32_t magic;
	uint32_t magic_inverse;
	size_t start;
	size_t length;
	char buffer[LOG_RAM_SIZE];
};

/* The linker leaves this region untouched during normal startup. */
static __noinit struct retained_log retained;
/* Bytes pushed out of the buffer since boot. Protected by log_lock. */
static uint64_t dropped;
static struct k_spinlock log_lock;
static uint8_t format_buffer[128];

static int store_output(uint8_t *data, size_t length, void *ctx)
{
	k_spinlock_key_t key;

	ARG_UNUSED(ctx);
	key = k_spin_lock(&log_lock);
	for (size_t i = 0; i < length; i++) {
		if (retained.length == LOG_RAM_SIZE) {
			retained.start = (retained.start + 1) % LOG_RAM_SIZE;
			retained.length--;
			dropped++;
		}
		retained.buffer[(retained.start + retained.length) % LOG_RAM_SIZE] = data[i];
		retained.length++;
	}
	k_spin_unlock(&log_lock, key);
	return (int)length;
}

LOG_OUTPUT_DEFINE(ram_output, store_output, format_buffer, sizeof(format_buffer));

static void ram_process(const struct log_backend *const backend, union log_msg_generic *msg)
{
	ARG_UNUSED(backend);
	log_output_msg_process(&ram_output, &msg->log,
			       LOG_OUTPUT_FLAG_TIMESTAMP | LOG_OUTPUT_FLAG_FORMAT_TIMESTAMP |
			       LOG_OUTPUT_FLAG_LEVEL | LOG_OUTPUT_FLAG_CRLF_LFONLY);
}

static void ram_panic(const struct log_backend *const backend)
{
	ARG_UNUSED(backend);
}

static log_timestamp_t timestamp_us(void)
{
	return k_cyc_to_us_floor64(k_cycle_get_64());
}

static void ram_init(const struct log_backend *const backend)
{
	ARG_UNUSED(backend);
	log_set_timestamp_func(timestamp_us, 1000000U);
	if (retained.magic != LOG_RAM_MAGIC || retained.magic_inverse != ~LOG_RAM_MAGIC ||
	    retained.start >= LOG_RAM_SIZE || retained.length > LOG_RAM_SIZE) {
		retained.start = 0;
		retained.length = 0;
		retained.magic_inverse = ~LOG_RAM_MAGIC;
		retained.magic = LOG_RAM_MAGIC;
	}
}

static const struct log_backend_api ram_backend_api = {
	.process = ram_process,
	.panic = ram_panic,
	.init = ram_init,
};

LOG_BACKEND_DEFINE(ram_backend, ram_backend_api, true);

/* Prints the log in pieces so that no second copy of it is needed. `dropped`
 * numbers the bytes from boot, which keeps the position valid when new
 * messages push old ones out while printing. */
static int cmd_dmesg(const struct shell *sh, size_t argc, char **argv)
{
	char piece[97];
	uint64_t position = 0;
	bool first = true, any = false;

	ARG_UNUSED(argc);
	ARG_UNUSED(argv);
	/* Bounded in case logging keeps up with printing. */
	for (size_t printed = 0; printed < 2U * LOG_RAM_SIZE;) {
		k_spinlock_key_t key = k_spin_lock(&log_lock);
		size_t available, n;

		if (first || position < dropped) {
			position = dropped; /* start, or skip what was overwritten */
			first = false;
		}
		available = (size_t)(dropped + retained.length - position);
		n = MIN(available, sizeof(piece) - 1);
		for (size_t k = 0; k < n; k++) {
			piece[k] = retained.buffer[(retained.start + (size_t)(position - dropped) + k) %
						   LOG_RAM_SIZE];
		}
		k_spin_unlock(&log_lock, key);
		if (!n) {
			break;
		}
		piece[n] = '\0';
		shell_fprintf(sh, SHELL_NORMAL, "%s", piece);
		position += n;
		printed += n;
		any = true;
	}
	if (!any) {
		shell_print(sh, "No logs.");
	}
	return 0;
}

SHELL_CMD_REGISTER(dmesg, NULL, "Show logs stored in RAM", cmd_dmesg);
```

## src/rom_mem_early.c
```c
/* SPDX-License-Identifier: MIT */
/* The memcpy() and memset() of the early boot with CONFIG_NANO_ROM_MEM_OPS.
 *
 * memcpy(), memset() and __aeabi_memcpy*()/__aeabi_memset*() are wrapped
 * (--wrap, CMakeLists.txt) to the bootrom's routines of
 * common/drivers/rp2040_rom, which look the routines up on first use and
 * keep them in .bss.  The kernel's weak arch_early_memset() and
 * arch_early_memcpy() (arch/common/init.c) call memset() and memcpy(): they
 * clear .bss and copy .data (z_bss_zero(), z_data_copy()) and fill the
 * interrupt stack before that (CONFIG_INIT_STACKS, cortex_m/reset.S), so
 * they must not go through the wrappers.  These call picolibc's own
 * routines, which need no state.
 */
#include <stddef.h>

#include <zephyr/arch/common/init.h>

void *__real_memcpy(void *dst, const void *src, size_t n);
void *__real_memset(void *dst, int c, size_t n);

void arch_early_memset(void *dst, int c, size_t n)
{
	(void)__real_memset(dst, c, n);
}

void arch_early_memcpy(void *dst, const void *src, size_t n)
{
	(void)__real_memcpy(dst, src, n);
}
```
